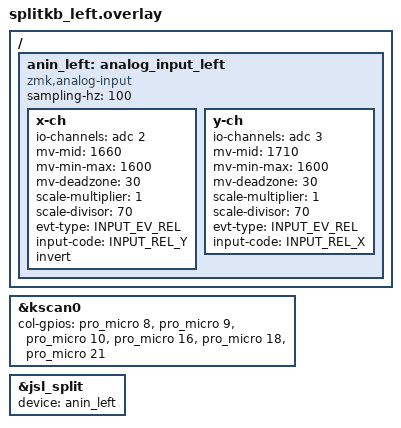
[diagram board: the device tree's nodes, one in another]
#include "splitkb.dtsi"

/*
 * Lado ESQUERDO — agora PERIFERICO (com o dongle, quem e central e o dongle).
 * Antes este lado era o central; por isso o joystick esquerdo era cursor local.
 * Agora ele alimenta o input-split (reg=1) igual o direito faz, e o listener
 * que vira isso em mouse mora no dongle.
 */

/* Colunas do lado ESQUERDO (C0..C5 = mindinho -> indice) */
&kscan0 {
    col-gpios
        = <&pro_micro 8  GPIO_ACTIVE_HIGH>
        , <&pro_micro 9  GPIO_ACTIVE_HIGH>
        , <&pro_micro 10 GPIO_ACTIVE_HIGH>
        , <&pro_micro 16 GPIO_ACTIVE_HIGH>
        , <&pro_micro 18 GPIO_ACTIVE_HIGH>
        , <&pro_micro 21 GPIO_ACTIVE_HIGH>
        ;
};

/ {
    /* Joystick ESQUERDO (periferico). Alimenta o input-split reg=1 -> dongle. */
    anin_left: analog_input_left {
        compatible = "zmk,analog-input";
        sampling-hz = <100>;

        x-ch {
            io-channels = <&adc 2>;
            mv-mid = <1660>;        /* calibrado no teste */
            mv-min-max = <1600>;
            mv-deadzone = <30>;
            scale-multiplier = <1>;
            scale-divisor = <70>;
            evt-type = <INPUT_EV_REL>;
            input-code = <INPUT_REL_Y>;
            invert;                   /* cima<->baixo invertido (eixo vertical) */
        };
        y-ch {
            io-channels = <&adc 3>;
            mv-mid = <1710>;
            mv-min-max = <1600>;
            mv-deadzone = <30>;
            scale-multiplier = <1>;
            scale-divisor = <70>;
            evt-type = <INPUT_EV_REL>;
            input-code = <INPUT_REL_X>;
        };
    };
};

/* Conecta o joystick esquerdo ao input-split reg=1 (lado periferico). */
&jsl_split {
    status = "okay";
    device = <&anin_left>;
};
